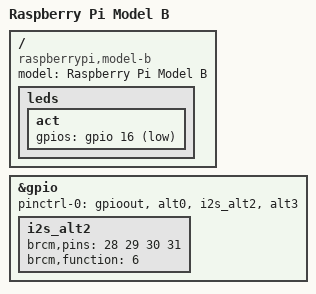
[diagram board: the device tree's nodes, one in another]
/dts-v1/;
/include/ "bcm2835-rpi.dtsi"
/* include할때 원래 이게 문법이고, #include는 나중에 지원한것.
   */

/ {
	compatible = "raspberrypi,model-b", "brcm,bcm2835";
	model = "Raspberry Pi Model B";

	leds {
		act {
			gpios = <&gpio 16 1>;
		};
	};
};

&gpio {
	pinctrl-0 = <&gpioout &alt0 &i2s_alt2 &alt3>;

	/* I2S interface */
	i2s_alt2: i2s_alt2 {
		brcm,pins = <28 29 30 31>;
		brcm,function = <6>; /* alt2 */
	};
};
